# ing920 register map
Vendor: INGChips; Series: ing920xx; File version: 1.0
CPU: CM3 r2p1, little endian, no MPU, no FPU, 2 interrupt priority bits
Registers are 32-bit, read-write, reset 0x0 unless marked. A register's access mark holds for its fields unless they carry their own. Offsets are from the block's base; [hi:lo] are bit positions.

## FLASH_SPI_CTRL
Base 0x40150000
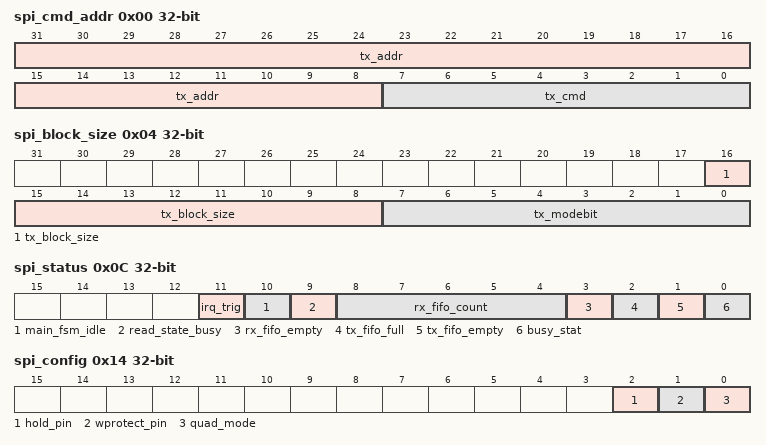
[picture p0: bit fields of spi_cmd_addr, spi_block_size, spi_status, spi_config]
0x00 spi_cmd_addr — reg description:
  [31:8] tx_addr — reg description:
  [7:0] tx_cmd — reg description:
0x04 spi_block_size — reg description:
  [16:8] tx_block_size — reg description:
  [7:0] tx_modebit — reg description:
0x08 spi_data_fifo — reg description:
0x0C spi_status — reg description:
  [11] irq_trig — reg description:
  [10] main_fsm_idle — reg description:
  [9] read_state_busy — reg description:
  [8:4] rx_fifo_count — reg description:
  [3] rx_fifo_empty — reg description:
  [2] tx_fifo_full — reg description:
  [1] tx_fifo_empty — reg description:
  [0] busy_stat — reg description:
0x10 rx_status — reg description:
0x14 spi_config — reg description:
  [2] hold_pin — reg description:
  [1] wprotect_pin — reg description:
  [0] quad_mode — reg description:
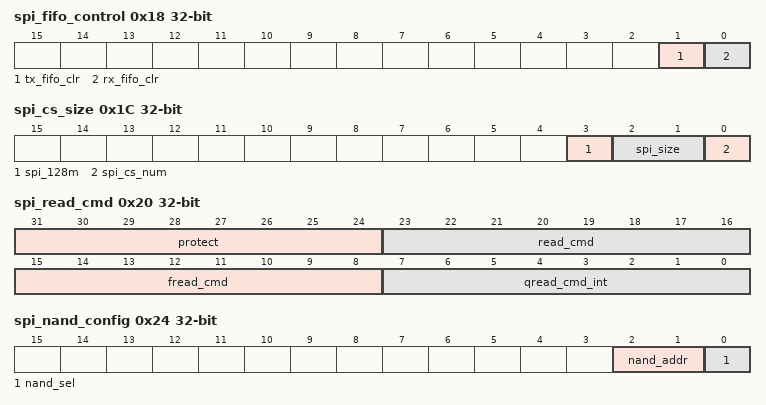
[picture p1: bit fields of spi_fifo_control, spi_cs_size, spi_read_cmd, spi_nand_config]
0x18 spi_fifo_control — reg description:
  [1] tx_fifo_clr — reg description:
  [0] rx_fifo_clr — reg description:
0x1C spi_cs_size — reg description:
  [3] spi_128m — reg description:
  [2:1] spi_size — reg description:
  [0] spi_cs_num — reg description:
0x20 spi_read_cmd — reg description:
  [31:24] protect — reg description:
  [23:16] read_cmd — reg description:
  [15:8] fread_cmd — reg description:
  [7:0] qread_cmd_int — reg description:
0x24 spi_nand_config — reg description:
  [2:1] nand_addr — reg description:
  [0] nand_sel — reg description:
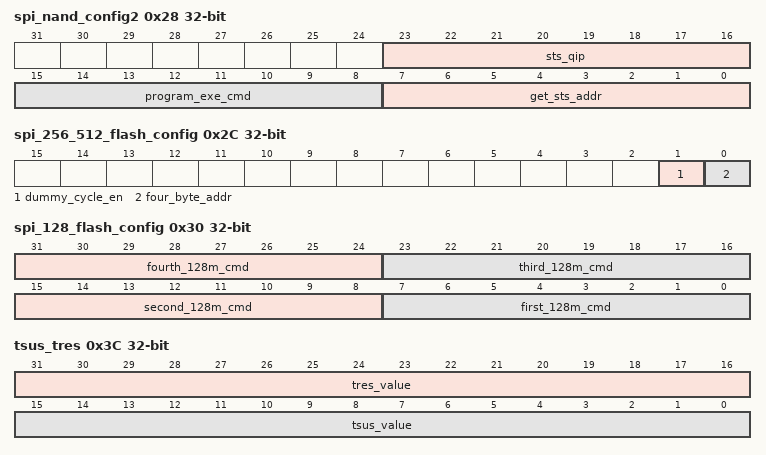
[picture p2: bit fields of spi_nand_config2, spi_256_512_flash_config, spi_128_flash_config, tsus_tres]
0x28 spi_nand_config2 — reg description:
  [23:16] sts_qip — reg description:
  [15:8] program_exe_cmd — reg description:
  [7:0] get_sts_addr — reg description:
0x2C spi_256_512_flash_config — reg description:
  [1] dummy_cycle_en — reg description:
  [0] four_byte_addr — reg description:
0x30 spi_128_flash_config — reg description:
  [31:24] fourth_128m_cmd — reg description:
  [23:16] third_128m_cmd — reg description:
  [15:8] second_128m_cmd — reg description:
  [7:0] first_128m_cmd — reg description:
0x34 timeout_value — reg description:
0x3C tsus_tres — reg description:
  [31:16] tres_value — reg description:
  [15:0] tsus_value — reg description:
0x40 flash_irq — reg description:
  [0] reg_irq
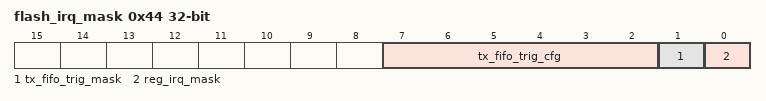
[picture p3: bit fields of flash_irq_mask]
0x44 flash_irq_mask — reg description:
  [7:2] tx_fifo_trig_cfg — reg description:
  [1] tx_fifo_trig_mask — reg description:
  [0] reg_irq_mask — reg description:

## key_scanner
Base 0x4000A000
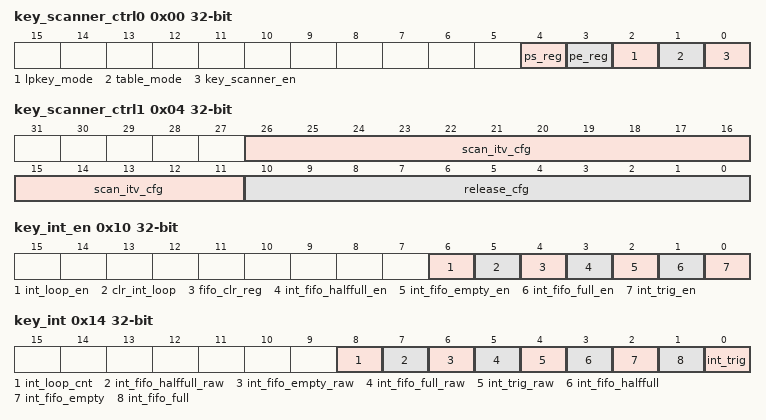
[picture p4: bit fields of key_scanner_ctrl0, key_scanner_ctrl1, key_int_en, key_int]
0x00 key_scanner_ctrl0 — reg description:
  [4] ps_reg — reg description:
  [3] pe_reg — reg description:
  [2] lpkey_mode — reg description:
  [1] table_mode — reg description:
  [0] key_scanner_en — reg description:
0x04 key_scanner_ctrl1 — reg description:
  [26:11] scan_itv_cfg — reg description:
  [10:0] release_cfg — reg description:
0x08 key_row_mask_ctrl — reg description:
  [7:0] key_mask_row
0x0C key_col_mask_ctrl — reg description:
  [21:0] key_mask_col
0x10 key_int_en — reg description:
  [6] int_loop_en — reg description:
  [5] clr_int_loop — reg description:
  [4] fifo_clr_reg — reg description:
  [3] int_fifo_halffull_en — reg description:
  [2] int_fifo_empty_en — reg description:
  [1] int_fifo_full_en — reg description:
  [0] int_trig_en — reg description:
0x14 key_int — reg description:
  [8] int_loop_cnt — reg description:
  [7] int_fifo_halffull_raw — reg description:
  [6] int_fifo_empty_raw — reg description:
  [5] int_fifo_full_raw — reg description:
  [4] int_trig_raw — reg description:
  [3] int_fifo_halffull — reg description:
  [2] int_fifo_empty — reg description:
  [1] int_fifo_full — reg description:
  [0] int_trig — reg description:
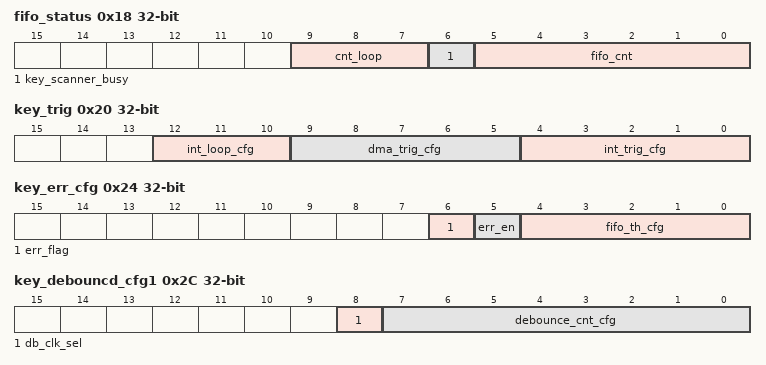
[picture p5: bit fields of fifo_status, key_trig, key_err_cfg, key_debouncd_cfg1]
0x18 fifo_status — reg description:
  [9:7] cnt_loop — reg description:
  [6] key_scanner_busy — reg description:
  [5:0] fifo_cnt — reg description:
0x1C key_data — reg description:
  [10:0] key_data
0x20 key_trig — reg description:
  [12:10] int_loop_cfg — reg description:
  [9:5] dma_trig_cfg — reg description:
  [4:0] int_trig_cfg — reg description:
0x24 key_err_cfg — reg description:
  [6] err_flag — reg description:
  [5] err_en — reg description:
  [4:0] fifo_th_cfg — reg description:
0x28 key_debouncd_cfg0 — reg description:
  [29:0] en_debounce
0x2C key_debouncd_cfg1 — reg description:
  [8] db_clk_sel — reg description:
  [7:0] debounce_cnt_cfg — reg description:
